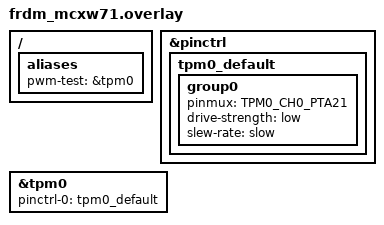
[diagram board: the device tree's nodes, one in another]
/*
 * Copyright 2025-2026 NXP
 *
 * SPDX-License-Identifier: Apache-2.0
 */
/ {
	aliases {
		pwm-test = &tpm0;
	};
};

/* To test this sample, check the wave from PTA21(J1-8). */
&pinctrl {
	tpm0_default: tpm0_default {
		group0 {
			pinmux = <TPM0_CH0_PTA21>;
			drive-strength = "low";
			slew-rate = "slow";
		};
	};
};

&tpm0 {
	status = "okay";
	pinctrl-0 = <&tpm0_default>;
	pinctrl-names = "default";
};
